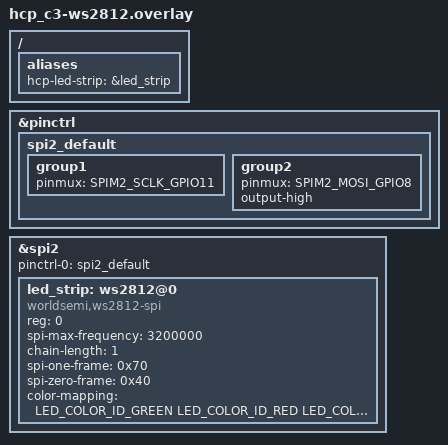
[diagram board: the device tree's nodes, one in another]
/*
 * ESP32-C3 specific: optional WS2812 binding for the hcp_c3 board.
 * Applied via: build.sh hcp_c3 --led
 * Strip data = SPI2 MOSI -> GPIO8 (CONFIRM your c3 board's RGB data pin).
 * SCLK -> GPIO11 (SPI clock only; not wired to the strip). GPIO6/7/8 are C3
 * strapping pins and GPIO6 is RX on the c3-485 variant, so avoid them here.
 */

#include <zephyr/dt-bindings/led/led.h>
#include <zephyr/dt-bindings/pinctrl/esp32c3-pinctrl.h>

/ {
	aliases {
		hcp-led-strip = &led_strip;
	};
};

&pinctrl {
	spi2_default: spi2_default {
		group1 {
			pinmux = <SPIM2_SCLK_GPIO11>;
		};
		group2 {
			pinmux = <SPIM2_MOSI_GPIO8>;
			output-high;
		};
	};
};

&spi2 {
	status = "okay";
	#address-cells = <1>;
	#size-cells = <0>;
	pinctrl-0 = <&spi2_default>;
	pinctrl-names = "default";

	led_strip: ws2812@0 {
		compatible = "worldsemi,ws2812-spi";
		reg = <0>;
		spi-max-frequency = <3200000>;
		chain-length = <1>;

		spi-one-frame = <0x70>;
		spi-zero-frame = <0x40>;

		color-mapping = <LED_COLOR_ID_GREEN
				 LED_COLOR_ID_RED
				 LED_COLOR_ID_BLUE>;
	};
};
